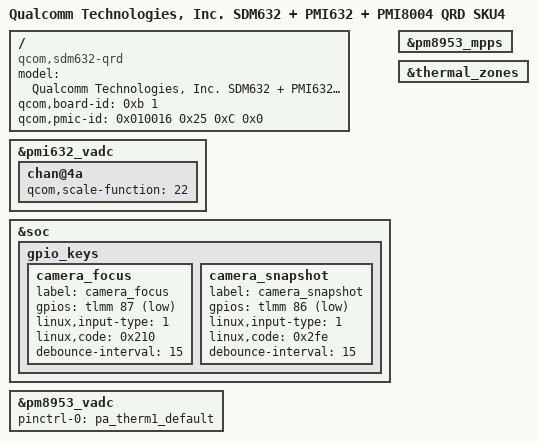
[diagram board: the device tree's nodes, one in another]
/*
 * Copyright (c) 2018, The Linux Foundation. All rights reserved.
 *
 * This program is free software; you can redistribute it and/or modify
 * it under the terms of the GNU General Public License version 2 and
 * only version 2 as published by the Free Software Foundation.
 *
 * This program is distributed in the hope that it will be useful,
 * but WITHOUT ANY WARRANTY; without even the implied warranty of
 * MERCHANTABILITY or FITNESS FOR A PARTICULAR PURPOSE.  See the
 * GNU General Public License for more details.
 */

/dts-v1/;

#include "sdm632.dtsi"
#include "sdm450-qrd-sku4.dtsi"
#include "sdm450-pmi632.dtsi"
#include "msm8953-camera-sensor-qrd.dtsi"

/ {
	model = "Qualcomm Technologies, Inc. SDM632 + PMI632 + PMI8004 QRD SKU4";
	compatible = "qcom,sdm632-qrd", "qcom,sdm632", "qcom,qrd";
	qcom,board-id = <0xb 1>;
	qcom,pmic-id = <0x010016 0x25 0xC 0x0>;
};

&pmi632_vadc {
	chan@4a {
		qcom,scale-function = <22>;
	};
};

&soc {
	gpio_keys {
		camera_focus {
			label = "camera_focus";
			gpios = <&tlmm 87 0x1>;
			linux,input-type = <1>;
			linux,code = <0x210>;
			debounce-interval = <15>;
		};

		camera_snapshot {
			label = "camera_snapshot";
			gpios = <&tlmm 86 0x1>;
			linux,input-type = <1>;
			linux,code = <0x2fe>;
			debounce-interval = <15>;
		};
	};
};

&pm8953_vadc {
	pinctrl-0 = <&pa_therm1_default>;
	/delete-node/ chan@13;
};

&pm8953_mpps {
	/delete-node/ case_therm;
};

&thermal_zones {
	/delete-node/ case-therm-adc;
	/delete-node/ case-therm-step;
};
